# STM32C5A3xx register map
File version: 1.0
Registers are 32-bit, read-write, reset 0x0 unless marked. A register's access mark holds for its fields unless they carry their own. Offsets are from the block's base; [hi:lo] are bit positions; {n}, {i} and the like mark numbered series.

## CRS — Clock Recovery System
Base 0x40006000
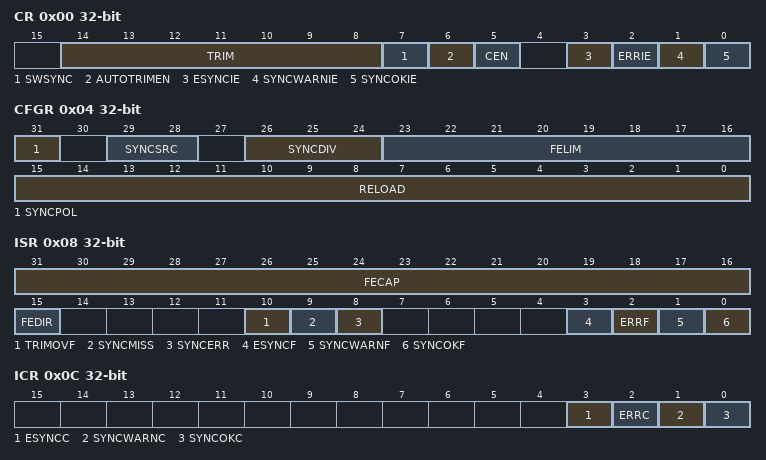
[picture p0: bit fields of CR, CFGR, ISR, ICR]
0x00 CR — CRS control register
  [14:8] TRIM — HSI144 oscillator smooth trimming
  [7] SWSYNC — Generate software SYNC event
  [6] AUTOTRIMEN — Automatic trimming enable
  [5] CEN — Frequency error counter enable
  [3] ESYNCIE — Expected SYNC interrupt enable
  [2] ERRIE — SYNC error or trimming error interrupt enable
  [1] SYNCWARNIE — SYNC warning interrupt enable
  [0] SYNCOKIE — SYNC event OK interrupt enable
0x04 CFGR — CRS configuration register
  [31] SYNCPOL — SYNC polarity selection
  [29:28] SYNCSRC — SYNC signal source selection
  [26:24] SYNCDIV — SYNC divider
  [23:16] FELIM — Frequency error limit
  [15:0] RELOAD — Counter reload value
0x08 ISR ro — CRS interrupt and status register
  [31:16] FECAP — Frequency error capture
  [15] FEDIR — Frequency error direction
  [10] TRIMOVF — Trimming overflow or underflow
  [9] SYNCMISS — SYNC missed
  [8] SYNCERR — SYNC error
  [3] ESYNCF — Expected SYNC flag
  [2] ERRF — Error flag
  [1] SYNCWARNF — SYNC warning flag
  [0] SYNCOKF — SYNC event OK flag
0x0C ICR — CRS interrupt flag clear register
  [3] ESYNCC — Expected SYNC clear flag
  [2] ERRC — Error clear flag
  [1] SYNCWARNC — SYNC warning clear flag
  [0] SYNCOKC — SYNC event OK clear flag

## FDCAN_CONFIG — FD Controller Area Network Configuration
Base 0x4000A500
0x00 CKDIV — FDCAN clock divider register
  [3:0] PDIV — Input Clock Divider

## USB_DRD_FS — Universal Serial Bus Full Speed Dual Role Device
Base 0x40016000
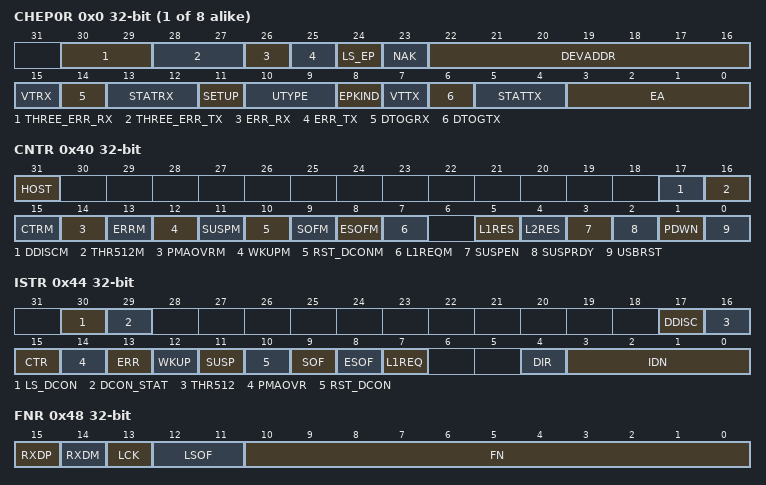
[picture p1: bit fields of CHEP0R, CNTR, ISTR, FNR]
{0x0+4i} CHEP{i}R (i=0..7) — USB Channel/Endpoint {i} register
  [30:29] THREE_ERR_RX — Three errors for an IN transaction
  [28:27] THREE_ERR_TX
  [26] ERR_RX — Received error for an IN transaction
  [25] ERR_TX
  [24] LS_EP — Low speed endpoint host with HUB only
  [23] NAK — Host mode
  [22:16] DEVADDR — Host mode
  [15] VTRX — USB valid transaction received
  [14] DTOGRX — Data Toggle, for reception transfers
  [13:12] STATRX — Status bits, for reception transfers
  [11] SETUP — Setup transaction completed
  [10:9] UTYPE — USB type of transaction
  [8] EPKIND — endpoint/channel kind
  [7] VTTX — Valid USB transaction transmitted
  [6] DTOGTX — Data toggle, for transmission transfers
  [5:4] STATTX — Status bits, for transmission transfers
  [3:0] EA — endpoint/channel address
0x40 CNTR — Control register
  [31] HOST — HOST mode
  [17] DDISCM — Device disconnection mask
  [16] THR512M — 512 byte threshold interrupt mask
  [15] CTRM — Correct transfer interrupt mask
  [14] PMAOVRM
  [13] ERRM — Error interrupt mask
  [12] WKUPM — Wake-up interrupt mask
  [11] SUSPM — Suspend mode interrupt mask
  [10] RST_DCONM
  [9] SOFM — Start of frame interrupt mask
  [8] ESOFM — Expected start of frame interrupt mask
  [7] L1REQM — LPM L1 state request interrupt mask
  [5] L1RES — L1 remote wake-up / resume driver
  [4] L2RES — L2 remote wake-up / resume driver
  [3] SUSPEN — Suspend state enable
  [2] SUSPRDY — Suspend state effective
  [1] PDWN — Power down
  [0] USBRST — USB Reset
0x44 ISTR — Interrupt status register
  [30] LS_DCON — Low speed device connected
  [29] DCON_STAT — Device connection status
  [17] DDISC — Device connection
  [16] THR512 — 512 byte threshold interrupt
  [15] CTR — Completed transfer in host mode
  [14] PMAOVR — Packet memory area over / underrun
  [13] ERR — Error
  [12] WKUP — Wake-up
  [11] SUSP — Suspend mode request
  [10] RST_DCON
  [9] SOF — Start of frame
  [8] ESOF — Expected start of frame
  [7] L1REQ — LPM L1 state request
  [4] DIR — Direction of transaction
  [3:0] IDN
0x48 FNR ro — Frame number register
  [15] RXDP — Receive data + line status
  [14] RXDM — Receive data - line status
  [13] LCK — Locked
  [12:11] LSOF — Lost SOF
  [10:0] FN — Frame number
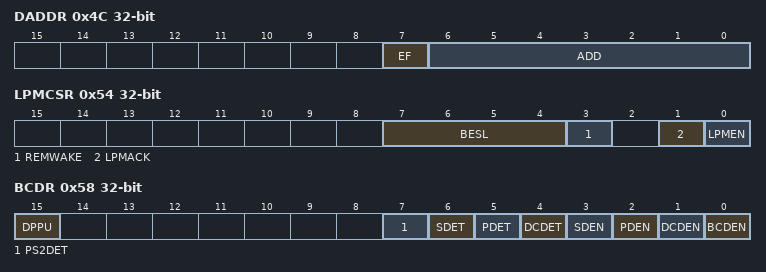
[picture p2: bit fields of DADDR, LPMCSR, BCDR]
0x4C DADDR — Device address register
  [7] EF — Enable function
  [6:0] ADD — Device address
0x54 LPMCSR — LPM Control and Status register
  [7:4] BESL — BESL value
  [3] REMWAKE — bRemoteWake value
  [1] LPMACK — LPM token acknowledge enable
  [0] LPMEN — LPM support enable
0x58 BCDR — Battery Charging detector register
  [15] DPPU
  [7] PS2DET — DM pull-up detection status
  [6] SDET — Secondary detection (SD) status
  [5] PDET — Primary detection (PD) status
  [4] DCDET — Data contact detection (DCD) status
  [3] SDEN — Secondary detection (SD) mode enable
  [2] PDEN — Primary detection (PD) mode enable
  [1] DCDEN
  [0] BCDEN — Battery charging detector (BCD) enable
